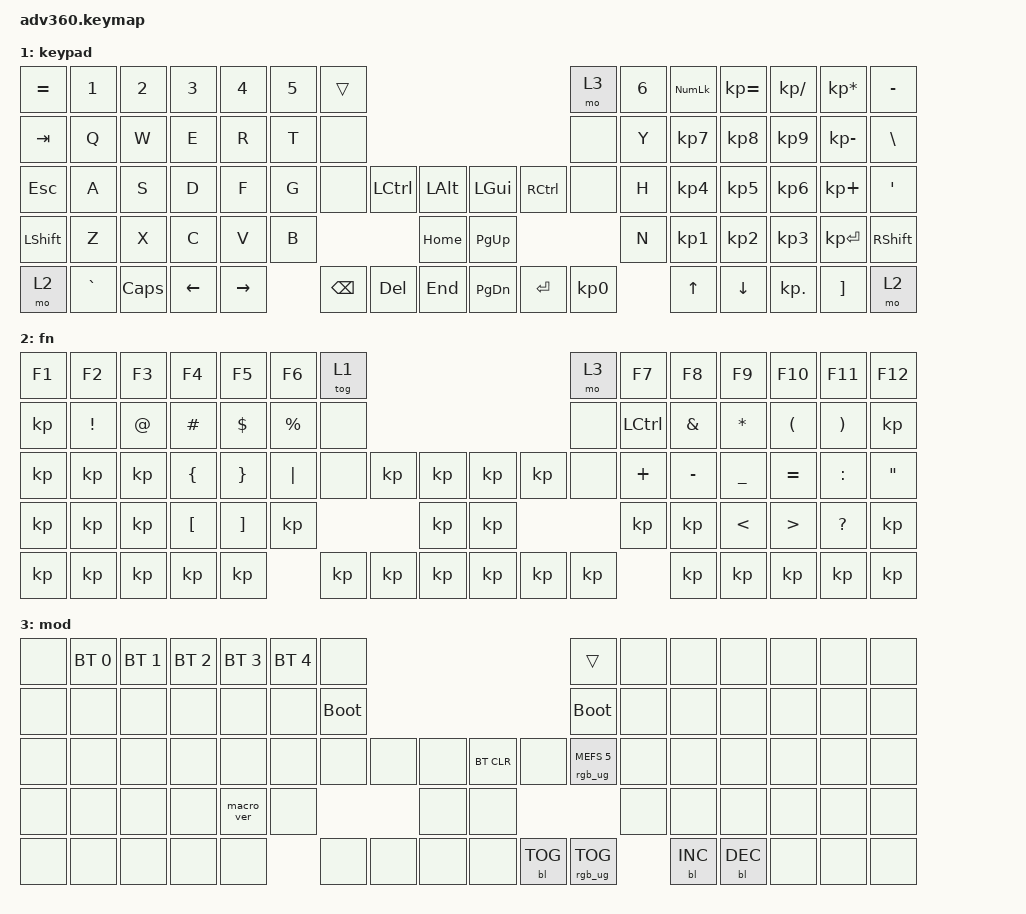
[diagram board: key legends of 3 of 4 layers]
#include <behaviors.dtsi>
#include <dt-bindings/zmk/backlight.h>
#include <dt-bindings/zmk/bt.h>
#include <dt-bindings/zmk/keys.h>
#include <dt-bindings/zmk/rgb.h>

/ {
    behaviors {
        #include "macros.dtsi"
      #include "version.dtsi"
      #ifndef VERSION_MACRO

        macro_ver: macro_ver {
            compatible = "zmk,behavior-macro";
            label = "macro_version";
            #binding-cells = <0>;
            bindings = <&kp RET>;
        };

        vimsave: vimsave {
            compatible = "zmk,behavior-macro";
            #binding-cells = <0>;
            bindings = <&kp ESCAPE &kp RS(COLON) &kp W &kp RET>;
            label = "VIMSAVE";
        };

        macro2: macro2 {
            compatible = "zmk,behavior-macro";
            #binding-cells = <0>;
            bindings = <&none &kp LS(I) &kp L &kp K &kp C &kp W &kp N0 &kp N1 &kp N0 &kp N8>;
            label = "MACRO2";
        };

        #endif

        hm: homerow_mods {
            compatible = "zmk,behavior-hold-tap";
            label = "HOMEROW_MODS";
            #binding-cells = <2>;
            tapping-term-ms = <200>;
            quick_tap_ms = <175>;
            flavor = "tap-preferred";
            bindings = <&kp>, <&kp>;

            hold-trigger-key-positions = <29 30 31 32 40 41 42 43>;
        };
    };

    macros {
    };

    keymap {
        compatible = "zmk,keymap";

        default_layer {
            bindings = <
&kp GRAVE  &kp N1              &kp N2          &kp N3              &kp N4            &kp N5  &kp DELETE                                                                                   &mo 3      &kp N6  &kp N7             &kp N8               &kp N9           &kp N0                       &kp MINUS
&kp TAB    &kp Q               &kp W           &kp E               &kp R             &kp T   &kp LS(LC(LG(NUMBER_4)))                                                                     &none      &kp Y   &kp U              &kp I                &kp O            &kp P                        &kp BSLH
&kp ESC    &hm LEFT_CONTROL A  &hm LEFT_ALT S  &hm LEFT_COMMAND D  &hm LEFT_SHIFT F  &kp G   &kp LG(LS(S))             &kp CAPSLOCK  &kp C_VOLUME_UP        &kp LGUI   &kp LG(LC(RCTRL))  &none      &kp H   &hm RIGHT_SHIFT J  &hm RIGHT_COMMAND K  &hm RIGHT_ALT L  &hm RIGHT_CONTROL SEMICOLON  &kp SQT
&kp LSHFT  &kp Z               &kp X           &kp C               &kp V             &kp B                                           &kp C_VOLUME_DOWN      &kp PG_UP                                &kp N   &kp M              &kp COMMA            &kp DOT          &kp FSLH                     &kp RSHFT
&mo 2      &kp GRAVE           &kp LEFT_ALT    &kp LEFT_COMMAND    &kp RIGHT                 &kp BSPC                  &mo 2         &kp K_MUTE             &vimsave   &kp ENTER          &kp SPACE          &kp LEFT           &kp DOWN             &kp UP_ARROW     &kp RIGHT                    &mo 2
            >;
        };

        keypad {
            bindings = <
&kp EQUAL  &kp N1     &kp N2    &kp N3    &kp N4     &kp N5  &trans                                                   &mo 3      &kp N6  &kp KP_NUM  &kp KP_EQUAL  &kp KP_DIVIDE  &kp KP_MULTIPLY  &kp MINUS
&kp TAB    &kp Q      &kp W     &kp E     &kp R      &kp T   &none                                                    &none      &kp Y   &kp KP_N7   &kp KP_N8     &kp KP_N9      &kp KP_MINUS     &kp BSLH
&kp ESC    &kp A      &kp S     &kp D     &kp F      &kp G   &none     &kp LCTRL  &kp LALT      &kp LGUI   &kp RCTRL  &none      &kp H   &kp KP_N4   &kp KP_N5     &kp KP_N6      &kp KP_PLUS      &kp SQT
&kp LSHFT  &kp Z      &kp X     &kp C     &kp V      &kp B                        &kp HOME      &kp PG_UP                        &kp N   &kp KP_N1   &kp KP_N2     &kp KP_N3      &kp KP_ENTER     &kp RSHFT
&mo 2      &kp GRAVE  &kp CAPS  &kp LEFT  &kp RIGHT          &kp BSPC  &kp DEL    &kp END       &kp PG_DN  &kp ENTER  &kp KP_N0          &kp UP      &kp DOWN      &kp KP_DOT     &kp RBKT         &mo 2
            >;
        };

        fn {
            bindings = <
&kp F1  &kp F2           &kp F3       &kp F4            &kp F5             &kp F6       &tog 1                          &mo 3  &kp F7     &kp F8         &kp F9          &kp F10               &kp F11                &kp F12
&kp     &kp EXCLAMATION  &kp AT_SIGN  &kp HASH          &kp DOLLAR         &kp PERCENT  &none                           &none  &kp LCTRL  &kp AMPERSAND  &kp ASTERISK    &kp LEFT_PARENTHESIS  &kp RIGHT_PARENTHESIS  &kp
&kp     &kp              &kp          &kp LEFT_BRACE    &kp RIGHT_BRACE    &kp PIPE     &none   &kp  &kp      &kp  &kp  &none  &kp PLUS   &kp MINUS      &kp UNDERSCORE  &kp EQUAL             &kp COLON              &kp DOUBLE_QUOTES
&kp     &kp              &kp          &kp LEFT_BRACKET  &kp RIGHT_BRACKET  &kp                       &kp      &kp              &kp        &kp            &kp LESS_THAN   &kp GREATER_THAN      &kp QUESTION           &kp
&kp     &kp              &kp          &kp               &kp                             &kp     &kp  &kp      &kp  &kp  &kp               &kp            &kp             &kp                   &kp                    &kp
            >;
        };

        mod {
            bindings = <
&none  &bt BT_SEL 0  &bt BT_SEL 1  &bt BT_SEL 2  &bt BT_SEL 3  &bt BT_SEL 4  &none                                                  &trans                  &none  &none       &none       &none  &none  &none
&none  &none         &none         &none         &none         &none         &bootloader                                            &bootloader             &none  &none       &none       &none  &none  &none
&none  &none         &none         &none         &none         &none         &none        &none  &none      &bt BT_CLR  &none       &rgb_ug RGB_MEFS_CMD 5  &none  &none       &none       &none  &none  &none
&none  &none         &none         &none         &macro_ver    &none                             &none      &none                                           &none  &none       &none       &none  &none  &none
&none  &none         &none         &none         &none                       &none        &none  &none      &none       &bl BL_TOG  &rgb_ug RGB_TOG                &bl BL_INC  &bl BL_DEC  &none  &none  &none
            >;
        };
    };
};
